# STM32F103 register map
Registers are 32-bit, read-write, reset 0x0 unless marked. A register's access mark holds for its fields unless they carry their own. Offsets are from the block's base; [hi:lo] are bit positions; {n}, {i} and the like mark numbered series; 'fields as' and 'values as' point back to an identical list.

## USART1 — Universal synchronous asynchronous receiver transmitter
Base 0x40013800
Same registers: USART2 0x40004400, USART3 0x40004800
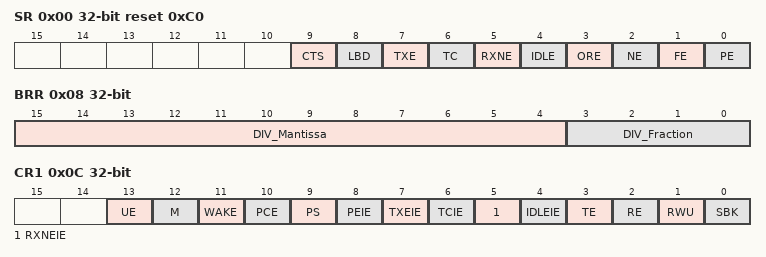
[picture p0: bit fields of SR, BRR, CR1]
0x00 SR reset 0xC0 — Status register
  [9] CTS — CTS flag
  [8] LBD — LIN break detection flag
  [7] TXE — Transmit data register empty
  [6] TC — Transmission complete
  [5] RXNE — Read data register not empty
  [4] IDLE — IDLE line detected
  [3] ORE — Overrun error
  [2] NE — Noise error flag
  [1] FE — Framing error
  [0] PE — Parity error
0x04 DR — Data register
  [8:0] DR — Data value
0x08 BRR — Baud rate register
  [15:4] DIV_Mantissa — Mantissa of USARTDIV
  [3:0] DIV_Fraction — Fraction of USARTDIV
0x0C CR1 — Control register 1
  [13] UE — USART enable
  [12] M — Word length
  [11] WAKE — Wakeup method
  [10] PCE — Parity control enable
  [9] PS — Parity selection
  [8] PEIE — PE interrupt enable
  [7] TXEIE — TXE interrupt enable
  [6] TCIE — Transmission complete interrupt enable
  [5] RXNEIE — RXNE interrupt enable
  [4] IDLEIE — IDLE interrupt enable
  [3] TE — Transmitter enable
  [2] RE — Receiver enable
  [1] RWU — Receiver wakeup
  [0] SBK — Send break
0x10 CR2 — Control register 2
  [13:12] STOP — Stop bits
0x14 CR3 — Control register 3
0x18 GTPR — Guard time and prescaler register

## RCC — Reset and clock control
Base 0x40021000
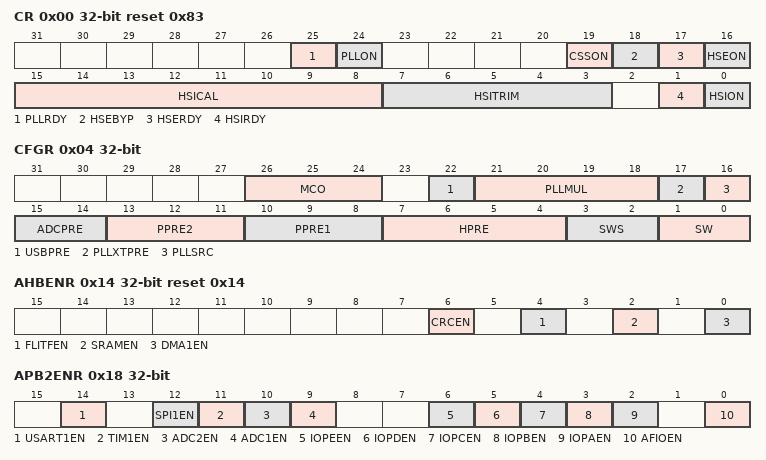
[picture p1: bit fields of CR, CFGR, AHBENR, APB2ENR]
0x00 CR reset 0x83 — Clock control register
  [25] PLLRDY — PLL clock ready flag
  [24] PLLON — PLL enable
  [19] CSSON — Clock security system enable
  [18] HSEBYP — External high-speed clock bypass
  [17] HSERDY — External high-speed clock ready flag
  [16] HSEON — External high-speed clock enable
  [15:8] HSICAL — Internal high-speed clock calibration
  [7:3] HSITRIM — Internal high-speed clock trimming
  [1] HSIRDY — Internal high-speed clock ready flag
  [0] HSION — Internal high-speed clock enable
0x04 CFGR — Clock configuration register
  [26:24] MCO — Microcontroller clock output
  [22] USBPRE — USB prescaler
  [21:18] PLLMUL — PLL multiplication factor
    {v}=Mul{v+2} (input clock times {v+2}) (v=0..14)
  [17] PLLXTPRE — HSE divider for PLL entry
  [16] PLLSRC — PLL entry clock source
    0=HSIDiv2 (HSI divided by 2); 1=HSE
  [15:14] ADCPRE — ADC prescaler
  [13:11] PPRE2 — APB high-speed prescaler (APB2)
    0=Div1 (not divided); 4=Div2 (divided by 2); 5=Div4 (divided by 4); 6=Div8 (divided by 8); 7=Div16 (divided by 16)
  [10:8] PPRE1 — APB low-speed prescaler (APB1)
    values as PPRE2
  [7:4] HPRE — AHB prescaler
    0=Div1 (not divided); 8=Div2 (divided by 2); 9=Div4 (divided by 4); 10=Div8 (divided by 8); 11=Div16 (divided by 16); 12=Div64 (divided by 64); 13=Div128 (divided by 128); 14=Div256 (divided by 256); 15=Div512 (divided by 512)
  [3:2] SWS — System clock switch status
    0=HSI (HSI oscillator); 1=HSE (HSE oscillator); 2=PLL
  [1:0] SW — System clock switch
    0=HSI (HSI oscillator); 1=HSE (HSE oscillator); 2=PLL
0x08 CIR — Clock interrupt register
0x0C APB2RSTR — APB2 peripheral reset register
0x10 APB1RSTR — APB1 peripheral reset register
0x14 AHBENR reset 0x14 — AHB peripheral clock enable register
  [6] CRCEN — CRC clock enable
  [4] FLITFEN — FLITF clock enable
  [2] SRAMEN — SRAM interface clock enable
  [0] DMA1EN — DMA1 clock enable
0x18 APB2ENR — APB2 peripheral clock enable register
  [14] USART1EN — USART1 clock enable
  [12] SPI1EN — SPI 1 clock enable
  [11] TIM1EN — TIM1 timer clock enable
  [10] ADC2EN — ADC 2 interface clock enable
  [9] ADC1EN — ADC 1 interface clock enable
  [6] IOPEEN — I/O port E clock enable
  [5] IOPDEN — I/O port D clock enable
  [4] IOPCEN — I/O port C clock enable
  [3] IOPBEN — I/O port B clock enable
  [2] IOPAEN — I/O port A clock enable
  [0] AFIOEN — Alternate function I/O clock enable
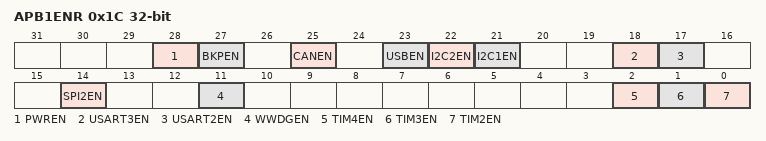
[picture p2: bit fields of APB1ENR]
0x1C APB1ENR — APB1 peripheral clock enable register
  [28] PWREN — Power interface clock enable
  [27] BKPEN — Backup interface clock enable
  [25] CANEN — CAN clock enable
  [23] USBEN — USB clock enable
  [22] I2C2EN — I2C 2 clock enable
  [21] I2C1EN — I2C 1 clock enable
  [18] USART3EN — USART 3 clock enable
  [17] USART2EN — USART 2 clock enable
  [14] SPI2EN — SPI 2 clock enable
  [11] WWDGEN — Window watchdog clock enable
  [2] TIM4EN — Timer 4 clock enable
  [1] TIM3EN — Timer 3 clock enable
  [0] TIM2EN — Timer 2 clock enable
0x20 BDCR — Backup domain control register
0x24 CSR reset 0xC000000 — Control and status register

## FLASH — Flash memory interface
Base 0x40022000
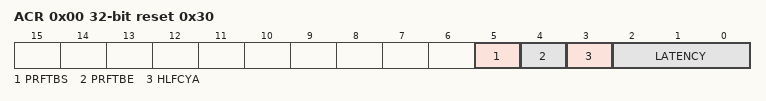
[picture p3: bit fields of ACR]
0x00 ACR reset 0x30 — Flash access control register
  [5] PRFTBS — Prefetch buffer status
  [4] PRFTBE — Prefetch buffer enable
  [3] HLFCYA — Flash half cycle access enable
  [2:0] LATENCY
    0=WS0 (zero wait states, for 24 MHz or less); 1=WS1 (one wait state, for 24 to 48 MHz); 2=WS2 (two wait states, for 48 to 72 MHz)

## STK — SysTick timer
Base 0xE000E010
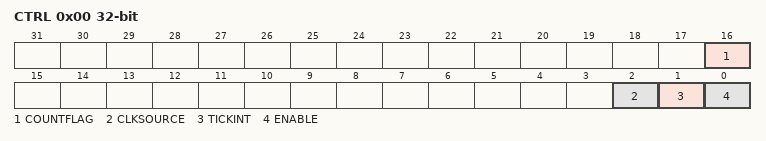
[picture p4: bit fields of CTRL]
0x00 CTRL — SysTick control and status register
  [16] COUNTFLAG — Counted to 0 since the last read
  [2] CLKSOURCE — Clock source selection
    0=External (the processor clock divided by 8); 1=Processor (the processor clock)
  [1] TICKINT — SysTick exception request enable
  [0] ENABLE — Counter enable
0x04 LOAD — SysTick reload value register
  [23:0] RELOAD — Reload value
0x08 VAL — SysTick current value register
  [23:0] CURRENT — Current counter value
0x0C CALIB ro reset 0x40002328 — SysTick calibration value register
  [23:0] TENMS — Calibration value

## NVIC — Nested vectored interrupt controller
Base 0xE000E100
0x00 ISER0 — Interrupt set-enable register 0: interrupts 0 to 31
0x04 ISER1 — Interrupt set-enable register 1: interrupts 32 to 63
0x80 ICER0 — Interrupt clear-enable register 0: interrupts 0 to 31
0x84 ICER1 — Interrupt clear-enable register 1: interrupts 32 to 63
0x100 ISPR0 — Interrupt set-pending register 0: interrupts 0 to 31
0x104 ISPR1 — Interrupt set-pending register 1: interrupts 32 to 63
0x180 ICPR0 — Interrupt clear-pending register 0: interrupts 0 to 31
0x184 ICPR1 — Interrupt clear-pending register 1: interrupts 32 to 63

## SCB — System control block
Base 0xE000ED00
0x00 CPUID ro reset 0x412FC231 — CPUID base register
0x04 ICSR — Interrupt control and state register
0x08 VTOR — Vector table offset register
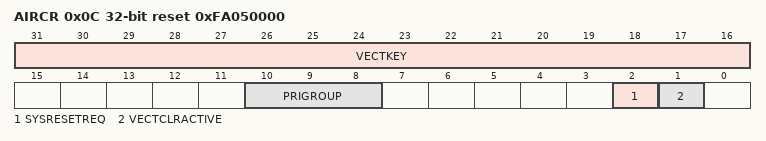
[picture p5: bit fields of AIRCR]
0x0C AIRCR reset 0xFA050000 — Application interrupt and reset control register
  [31:16] VECTKEY — Register key: 0x05FA on write
  [10:8] PRIGROUP — Interrupt priority grouping
  [2] SYSRESETREQ — System reset request
  [1] VECTCLRACTIVE — Clear the active state of exceptions
0x10 SCR — System control register
0x14 CCR — Configuration and control register
